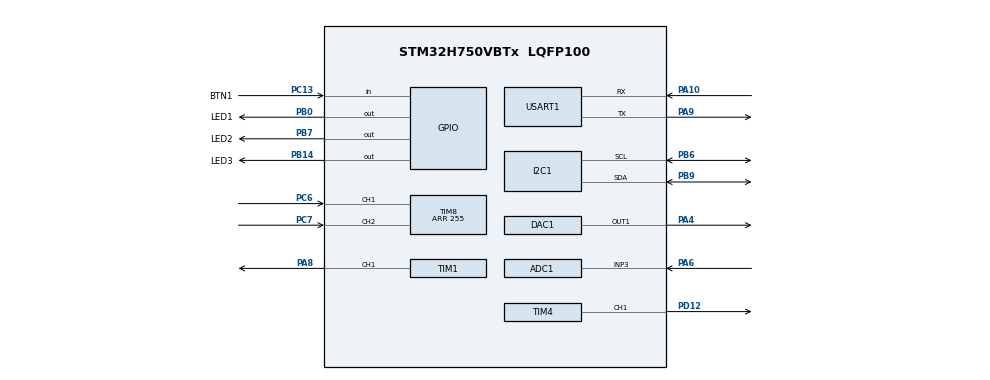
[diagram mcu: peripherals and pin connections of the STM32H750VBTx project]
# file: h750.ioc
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ADC1.Channel-0\#ChannelRegularConversion=ADC_CHANNEL_3
ADC1.ClockPrescaler=ADC_CLOCK_ASYNC_DIV8
ADC1.ContinuousConvMode=ENABLE
ADC1.ConversionDataManagement=ADC_CONVERSIONDATA_DMA_CIRCULAR
ADC1.DMAAccessModeView=ENABLE
ADC1.EOCSelection=ADC_EOC_SEQ_CONV
ADC1.Mode=ADC_DUALMODE_INTERL
ADC1.NbrOfConversionFlag=1
ADC1.OffsetNumber-0\#ChannelRegularConversion=ADC_OFFSET_NONE
ADC1.OffsetSignedSaturation-0\#ChannelRegularConversion=DISABLE
ADC1.Overrun=ADC_OVR_DATA_OVERWRITTEN
ADC1.Rank-0\#ChannelRegularConversion=1
ADC1.Resolution=ADC_RESOLUTION_8B
ADC1.SamplingTime-0\#ChannelRegularConversion=ADC_SAMPLETIME_32CYCLES_5
ADC1.TwoSamplingDelay=ADC_TWOSAMPLINGDELAY_2CYCLES
ADC1.master=1
ADC2.Channel-0\#ChannelRegularConversion=ADC_CHANNEL_3
ADC2.ClockPrescaler=ADC_CLOCK_ASYNC_DIV8
ADC2.ContinuousConvMode=ENABLE
ADC2.ConversionDataManagement=ADC_CONVERSIONDATA_DR
ADC2.DMAAccessModeView=ENABLE
ADC2.EOCSelection=ADC_EOC_SEQ_CONV
ADC2.Mode=ADC_DUALMODE_INTERL
ADC2.NbrOfConversionFlag=1
ADC2.OffsetNumber-0\#ChannelRegularConversion=ADC_OFFSET_NONE
ADC2.OffsetSignedSaturation-0\#ChannelRegularConversion=DISABLE
ADC2.Overrun=ADC_OVR_DATA_OVERWRITTEN
ADC2.Rank-0\#ChannelRegularConversion=1
ADC2.Resolution=ADC_RESOLUTION_8B
ADC2.SamplingTime-0\#ChannelRegularConversion=ADC_SAMPLETIME_32CYCLES_5
ADC2.TwoSamplingDelay=ADC_TWOSAMPLINGDELAY_2CYCLES
CORTEX_M7.CPU_DCache=Disabled
CORTEX_M7.CPU_ICache=Enabled
CORTEX_M7.MPU_Control=__NULL
DAC1.DAC1_OutputBuffer-DAC_OUT1=DAC_OUTPUTBUFFER_DISABLE
DAC1.DAC_Channel-DAC_OUT1=DAC_CHANNEL_1
DAC1.DAC_Trigger-DAC_OUT1=DAC_TRIGGER_T4_TRGO
DAC1.DAC_UserTrimming-DAC_OUT1=DAC_TRIMMING_FACTORY
DAC1.WaveGeneration-DAC_OUT1=DISABLE
Dma.ADC1.2.Direction=DMA_PERIPH_TO_MEMORY
Dma.ADC1.2.EventEnable=DISABLE
Dma.ADC1.2.FIFOMode=DMA_FIFOMODE_DISABLE
Dma.ADC1.2.Instance=DMA2_Stream0
Dma.ADC1.2.MemDataAlignment=DMA_MDATAALIGN_HALFWORD
Dma.ADC1.2.MemInc=DMA_MINC_ENABLE
Dma.ADC1.2.Mode=DMA_NORMAL
Dma.ADC1.2.PeriphDataAlignment=DMA_PDATAALIGN_HALFWORD
Dma.ADC1.2.PeriphInc=DMA_PINC_DISABLE
Dma.ADC1.2.Polarity=HAL_DMAMUX_REQ_GEN_RISING
Dma.ADC1.2.Priority=DMA_PRIORITY_VERY_HIGH
Dma.ADC1.2.RequestNumber=1
Dma.ADC1.2.SignalID=NONE
Dma.ADC1.2.SyncEnable=DISABLE
Dma.ADC1.2.SyncPolarity=HAL_DMAMUX_SYNC_NO_EVENT
Dma.ADC1.2.SyncRequestNumber=1
Dma.ADC1.2.SyncSignalID=NONE
Dma.DAC1_CH1.0.Direction=DMA_MEMORY_TO_PERIPH
Dma.DAC1_CH1.0.EventEnable=DISABLE
Dma.DAC1_CH1.0.FIFOMode=DMA_FIFOMODE_DISABLE
Dma.DAC1_CH1.0.Instance=DMA1_Stream2
Dma.DAC1_CH1.0.MemDataAlignment=DMA_MDATAALIGN_BYTE
Dma.DAC1_CH1.0.MemInc=DMA_MINC_ENABLE
Dma.DAC1_CH1.0.Mode=DMA_CIRCULAR
Dma.DAC1_CH1.0.PeriphDataAlignment=DMA_PDATAALIGN_BYTE
Dma.DAC1_CH1.0.PeriphInc=DMA_PINC_DISABLE
Dma.DAC1_CH1.0.Polarity=HAL_DMAMUX_REQ_GEN_RISING
Dma.DAC1_CH1.0.Priority=DMA_PRIORITY_HIGH
Dma.DAC1_CH1.0.RequestNumber=1
Dma.DAC1_CH1.0.SignalID=NONE
Dma.DAC1_CH1.0.SyncEnable=DISABLE
Dma.DAC1_CH1.0.SyncPolarity=HAL_DMAMUX_SYNC_NO_EVENT
Dma.DAC1_CH1.0.SyncRequestNumber=1
Dma.DAC1_CH1.0.SyncSignalID=NONE
Dma.Request0=DAC1_CH1
Dma.Request1=USART1_TX
Dma.Request2=ADC1
Dma.USART1_TX.1.Direction=DMA_MEMORY_TO_PERIPH
Dma.USART1_TX.1.EventEnable=DISABLE
Dma.USART1_TX.1.FIFOMode=DMA_FIFOMODE_DISABLE
Dma.USART1_TX.1.Instance=DMA1_Stream0
Dma.USART1_TX.1.MemDataAlignment=DMA_MDATAALIGN_BYTE
Dma.USART1_TX.1.MemInc=DMA_MINC_ENABLE
Dma.USART1_TX.1.Mode=DMA_NORMAL
Dma.USART1_TX.1.PeriphDataAlignment=DMA_PDATAALIGN_BYTE
Dma.USART1_TX.1.PeriphInc=DMA_PINC_DISABLE
Dma.USART1_TX.1.Polarity=HAL_DMAMUX_REQ_GEN_RISING
Dma.USART1_TX.1.Priority=DMA_PRIORITY_LOW
Dma.USART1_TX.1.RequestNumber=1
Dma.USART1_TX.1.SignalID=NONE
Dma.USART1_TX.1.SyncEnable=DISABLE
Dma.USART1_TX.1.SyncPolarity=HAL_DMAMUX_SYNC_NO_EVENT
Dma.USART1_TX.1.SyncRequestNumber=1
Dma.USART1_TX.1.SyncSignalID=NONE
I2C1.Timing=0x10C0ECFF
Mcu.Family=STM32H7
Mcu.Name=STM32H750VBTx
Mcu.Package=LQFP100
NVIC.DMA1_Stream0_IRQn=true\:0\:0\:false\:false\:true\:false\:true\:true
NVIC.DMA1_Stream2_IRQn=true\:0\:0\:false\:false\:true\:false\:true\:true
NVIC.DMA2_Stream0_IRQn=true\:0\:0\:false\:false\:true\:false\:true\:true
NVIC.PriorityGroup=NVIC_PRIORITYGROUP_4
PA10.Mode=Asynchronous
PA10.Signal=USART1_RX
PA13\ (JTMS/SWDIO).Mode=Serial_Wire
PA13\ (JTMS/SWDIO).Signal=DEBUG_JTMS-SWDIO
PA14\ (JTCK/SWCLK).Mode=Serial_Wire
PA14\ (JTCK/SWCLK).Signal=DEBUG_JTCK-SWCLK
PA4.Signal=COMP_DAC11_group
PA6.Signal=ADCx_INP3
PA8.GPIO_Speed=GPIO_SPEED_FREQ_HIGH
PA8.Signal=S_TIM1_CH1
PA9.Mode=Asynchronous
PA9.Signal=USART1_TX
PB0.GPIO_Label=LED1
PB0.GPIO_Speed=GPIO_SPEED_FREQ_LOW
PB0.Signal=GPIO_Output
PB14.GPIO_Label=LED3
PB14.GPIO_Speed=GPIO_SPEED_FREQ_LOW
PB14.Signal=GPIO_Output
PB6.Mode=I2C
PB6.Signal=I2C1_SCL
PB7.GPIO_Label=LED2
PB7.GPIO_Speed=GPIO_SPEED_FREQ_LOW
PB7.Signal=GPIO_Output
PB9.Mode=I2C
PB9.Signal=I2C1_SDA
PC13.GPIO_Label=BTN1
PC13.GPIO_PuPd=GPIO_PULLDOWN
PC13.Signal=GPIO_Input
PC6.GPIO_PuPd=GPIO_PULLUP
PC6.Signal=S_TIM8_CH1
PC7.GPIO_PuPd=GPIO_PULLUP
PC7.Signal=S_TIM8_CH2
PD0.Signal=FMC_D2_DA2
PD1.Signal=FMC_D3_DA3
PD10.Signal=FMC_D15_DA15
PD12.GPIO_Speed=GPIO_SPEED_FREQ_HIGH
PD12.Signal=S_TIM4_CH1
PD13.Signal=FMC_A18
PD14.Signal=FMC_D0_DA0
PD15.Signal=FMC_D1_DA1
PD4.Signal=FMC_NOE
PD5.Signal=FMC_NWE
PD7.Signal=FMC_NE1
PD8.Signal=FMC_D13_DA13
PD9.Signal=FMC_D14_DA14
PE10.Signal=FMC_D7_DA7
PE11.Signal=FMC_D8_DA8
PE12.Signal=FMC_D9_DA9
PE13.Signal=FMC_D10_DA10
PE14.Signal=FMC_D11_DA11
PE15.Signal=FMC_D12_DA12
PE7.Signal=FMC_D4_DA4
PE8.Signal=FMC_D5_DA5
PE9.Signal=FMC_D6_DA6
PH0-OSC_IN\ (PH0).Mode=HSE-External-Oscillator
PH0-OSC_IN\ (PH0).Signal=RCC_OSC_IN
PH1-OSC_OUT\ (PH1).Mode=HSE-External-Oscillator
PH1-OSC_OUT\ (PH1).Signal=RCC_OSC_OUT
ProjectManager.HeapSize=0x200
ProjectManager.StackSize=0x400
ProjectManager.TargetToolchain=STM32CubeIDE
RCC.ADCCLockSelection=RCC_ADCCLKSOURCE_PLL3
RCC.ADCFreq_Value=40000000
RCC.APB1Freq_Value=100000000
RCC.APB2Freq_Value=100000000
RCC.APB3Freq_Value=100000000
RCC.APB4Freq_Value=100000000
RCC.CortexFreq_Value=400000000
RCC.D1PPRE=RCC_APB3_DIV2
RCC.D2PPRE1=RCC_APB1_DIV2
RCC.D2PPRE2=RCC_APB2_DIV2
RCC.D3PPRE=RCC_APB4_DIV2
RCC.DIVM1=1
RCC.DIVM2=2
RCC.DIVM3=4
RCC.DIVN1=50
RCC.DIVN2=20
RCC.DIVN3=40
RCC.DIVR2=1
RCC.DIVR3=4
RCC.EnbaleCSS=true
RCC.FMCCLockSelection=RCC_FMCCLKSOURCE_PLL2
RCC.HCLKFreq_Value=200000000
RCC.HPRE=RCC_HCLK_DIV2
RCC.HSE_VALUE=16000000
RCC.LPTIM1CLockSelection=RCC_LPTIM1CLKSOURCE_PLL2
RCC.PLLSourceVirtual=RCC_PLLSOURCE_HSE
RCC.ProductRev=revY
RCC.SYSCLKFreq_VALUE=400000000
RCC.SYSCLKSource=RCC_SYSCLKSOURCE_PLLCLK
RCC.USBFreq_Value=400000000
SH.ADCx_INP3.0=ADC1_INP3,IN3-Single-Ended
SH.ADCx_INP3.1=ADC2_INP3,IN3-Single-Ended
SH.COMP_DAC11_group.0=DAC1_OUT1,DAC_OUT1
SH.FMC_A18.0=FMC_A18
SH.FMC_D0_DA0.0=FMC_D0
SH.FMC_D10_DA10.0=FMC_D10
SH.FMC_D11_DA11.0=FMC_D11
SH.FMC_D12_DA12.0=FMC_D12
SH.FMC_D13_DA13.0=FMC_D13
SH.FMC_D14_DA14.0=FMC_D14
SH.FMC_D15_DA15.0=FMC_D15
SH.FMC_D1_DA1.0=FMC_D1
SH.FMC_D2_DA2.0=FMC_D2
SH.FMC_D3_DA3.0=FMC_D3
SH.FMC_D4_DA4.0=FMC_D4
SH.FMC_D5_DA5.0=FMC_D5
SH.FMC_D6_DA6.0=FMC_D6
SH.FMC_D7_DA7.0=FMC_D7
SH.FMC_D8_DA8.0=FMC_D8
SH.FMC_D9_DA9.0=FMC_D9
SH.FMC_NOE.0=FMC_NOE
SH.FMC_NWE.0=FMC_NWE
SH.S_TIM1_CH1.0=TIM1_CH1,PWM Generation1 CH1
SH.S_TIM4_CH1.0=TIM4_CH1,PWM Generation1 CH1
SH.S_TIM8_CH1.0=TIM8_CH1,Encoder_Interface
SH.S_TIM8_CH2.0=TIM8_CH2,Encoder_Interface
TIM1.Channel-PWM\ Generation1\ CH1=TIM_CHANNEL_1
TIM1.Period=99
TIM1.Prescaler=99
TIM1.Pulse-PWM\ Generation1\ CH1=40
TIM4.Channel-PWM\ Generation1\ CH1=TIM_CHANNEL_1
TIM4.Period=5
TIM4.Prescaler=10
TIM4.Pulse-PWM\ Generation1\ CH1=3
TIM4.TIM_MasterOutputTrigger=TIM_TRGO_UPDATE
TIM8.EncoderMode=TIM_ENCODERMODE_TI12
TIM8.IC1Filter=6
TIM8.IC2Filter=6
TIM8.Period=255
USART1.DMADisableonRxErrorParam=ADVFEATURE_DMA_DISABLEONRXERROR
USART1.OverrunDisableParam=ADVFEATURE_OVERRUN_DISABLE
USART1.VirtualMode-Asynchronous=VM_ASYNC
VP_MEMORYMAP_VS_MEMORYMAP.Mode=CurAppReg
VP_TIM1_VS_ClockSourceINT.Mode=Internal
VP_TIM4_VS_ClockSourceINT.Mode=Internal
board=custom

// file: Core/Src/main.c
/* USER CODE BEGIN Header */
/**
  ******************************************************************************
  * @file           : main.c
  * @brief          : Main program body
  ******************************************************************************
  * @attention
  *
  * Copyright (c) 2026 STMicroelectronics.
  * All rights reserved.
  *
  * This software is licensed under terms that can be found in the LICENSE file
  * in the root directory of this software component.
  * If no LICENSE file comes with this software, it is provided AS-IS.
  *
  ******************************************************************************
  */
/* USER CODE END Header */
#include "main.h"

/* USER CODE BEGIN Includes */
#include "_main.h"

/* USER CODE END Includes */

void SystemClock_Config(void);
void PeriphCommonClock_Config(void);
static void MX_GPIO_Init(void);
static void MX_DMA_Init(void);
static void MX_USART1_UART_Init(void);
static void MX_TIM1_Init(void);
static void MX_TIM8_Init(void);
static void MX_DAC1_Init(void);
static void MX_TIM4_Init(void);
static void MX_ADC1_Init(void);
static void MX_ADC2_Init(void);
static void MX_I2C1_Init(void);

int main(void)
{

  /* Enable the CPU Cache */

  /* Enable I-Cache---------------------------------------------------------*/
  SCB_EnableICache();

  /* MCU Configuration--------------------------------------------------------*/

  /* Reset of all peripherals, Initializes the Flash interface and the Systick. */
  LL_APB4_GRP1_EnableClock(LL_APB4_GRP1_PERIPH_SYSCFG);

  /* System interrupt init*/
  NVIC_SetPriorityGrouping(NVIC_PRIORITYGROUP_4);

  /* SysTick_IRQn interrupt configuration */
  NVIC_SetPriority(SysTick_IRQn, NVIC_EncodePriority(NVIC_GetPriorityGrouping(),15, 0));

  /* Configure the system clock */
  SystemClock_Config();

  /* Configure the peripherals common clocks */
  PeriphCommonClock_Config();

  /* Initialize all configured peripherals */
  MX_GPIO_Init();
  MX_DMA_Init();
  MX_USART1_UART_Init();
  MX_TIM1_Init();
  MX_TIM8_Init();
  MX_DAC1_Init();
  MX_TIM4_Init();
  MX_ADC1_Init();
  MX_ADC2_Init();
  MX_I2C1_Init();
  /* USER CODE BEGIN 2 */

  // start uart
  DMA1_0_busy = 0;
  LL_DMA_EnableIT_TC(DMA1, LL_DMA_STREAM_0);
  LL_DMA_EnableIT_TE(DMA1, LL_DMA_STREAM_0);
  LL_USART_EnableDMAReq_TX(USART1);
  LL_USART_EnableDirectionTx(USART1);

  mainInitialize();

  /* USER CODE END 2 */

  /* Infinite loop */
  /* USER CODE BEGIN WHILE */

  // ReSharper disable once CppDFAEndlessLoop
  while (1)
  {
      mainCycle();
    /* USER CODE END WHILE */

  }
}

void SystemClock_Config(void)
{
  LL_FLASH_SetLatency(LL_FLASH_LATENCY_2);
  while(LL_FLASH_GetLatency()!= LL_FLASH_LATENCY_2)
  {
  }
  LL_PWR_ConfigSupply(LL_PWR_LDO_SUPPLY);
  LL_PWR_SetRegulVoltageScaling(LL_PWR_REGU_VOLTAGE_SCALE1);
  while (LL_PWR_IsActiveFlag_VOS() == 0)
  {
  }
  LL_RCC_HSE_Enable();

   /* Wait till HSE is ready */
  while(LL_RCC_HSE_IsReady() != 1)
  {

  }
  LL_RCC_HSE_EnableCSS();
  LL_RCC_PLL_SetSource(LL_RCC_PLLSOURCE_HSE);
  LL_RCC_PLL1P_Enable();
  LL_RCC_PLL1R_Enable();
  LL_RCC_PLL1_SetVCOInputRange(LL_RCC_PLLINPUTRANGE_8_16);
  LL_RCC_PLL1_SetVCOOutputRange(LL_RCC_PLLVCORANGE_WIDE);
  LL_RCC_PLL1_SetM(1);
  LL_RCC_PLL1_SetN(50);
  LL_RCC_PLL1_SetP(2);
  LL_RCC_PLL1_SetQ(2);
  LL_RCC_PLL1_SetR(2);
  LL_RCC_PLL1_Enable();

   /* Wait till PLL is ready */
  while(LL_RCC_PLL1_IsReady() != 1)
  {
  }

   /* Intermediate AHB prescaler 2 when target frequency clock is higher than 80 MHz */
   LL_RCC_SetAHBPrescaler(LL_RCC_AHB_DIV_2);

  LL_RCC_SetSysClkSource(LL_RCC_SYS_CLKSOURCE_PLL1);

   /* Wait till System clock is ready */
  while(LL_RCC_GetSysClkSource() != LL_RCC_SYS_CLKSOURCE_STATUS_PLL1)
  {

  }
  LL_RCC_SetSysPrescaler(LL_RCC_SYSCLK_DIV_1);
  LL_RCC_SetAHBPrescaler(LL_RCC_AHB_DIV_2);
  LL_RCC_SetAPB1Prescaler(LL_RCC_APB1_DIV_2);
  LL_RCC_SetAPB2Prescaler(LL_RCC_APB2_DIV_2);
  LL_RCC_SetAPB3Prescaler(LL_RCC_APB3_DIV_2);
  LL_RCC_SetAPB4Prescaler(LL_RCC_APB4_DIV_2);

  LL_Init1msTick(400000000);

  LL_SetSystemCoreClock(400000000);
  LL_RCC_HSE_EnableCSS();
}

void PeriphCommonClock_Config(void)
{
  LL_RCC_PLL3R_Enable();
  LL_RCC_PLL3_SetVCOInputRange(LL_RCC_PLLINPUTRANGE_4_8);
  LL_RCC_PLL3_SetVCOOutputRange(LL_RCC_PLLVCORANGE_MEDIUM);
  LL_RCC_PLL3_SetM(4);
  LL_RCC_PLL3_SetN(40);
  LL_RCC_PLL3_SetP(2);
  LL_RCC_PLL3_SetQ(2);
  LL_RCC_PLL3_SetR(4);
  LL_RCC_PLL3_Enable();

   /* Wait till PLL is ready */
  while(LL_RCC_PLL3_IsReady() != 1)
  {
  }

}

static void MX_ADC1_Init(void)
{

  LL_ADC_InitTypeDef ADC_InitStruct = {0};
  LL_ADC_REG_InitTypeDef ADC_REG_InitStruct = {0};
  LL_ADC_CommonInitTypeDef ADC_CommonInitStruct = {0};

  LL_GPIO_InitTypeDef GPIO_InitStruct = {0};

  LL_RCC_SetADCClockSource(LL_RCC_ADC_CLKSOURCE_PLL3R);

  /* Peripheral clock enable */
  LL_AHB1_GRP1_EnableClock(LL_AHB1_GRP1_PERIPH_ADC12);

  LL_AHB4_GRP1_EnableClock(LL_AHB4_GRP1_PERIPH_GPIOA);
  /**ADC1 GPIO Configuration
  PA6   ------> ADC1_INP3
  */
  GPIO_InitStruct.Pin = LL_GPIO_PIN_6;
  GPIO_InitStruct.Mode = LL_GPIO_MODE_ANALOG;
  GPIO_InitStruct.Pull = LL_GPIO_PULL_NO;
  LL_GPIO_Init(GPIOA, &GPIO_InitStruct);

  /* ADC1 DMA Init */

  /* ADC1 Init */
  LL_DMA_SetPeriphRequest(DMA2, LL_DMA_STREAM_0, LL_DMAMUX1_REQ_ADC1);

  LL_DMA_SetDataTransferDirection(DMA2, LL_DMA_STREAM_0, LL_DMA_DIRECTION_PERIPH_TO_MEMORY);

  LL_DMA_SetStreamPriorityLevel(DMA2, LL_DMA_STREAM_0, LL_DMA_PRIORITY_VERYHIGH);

  LL_DMA_SetMode(DMA2, LL_DMA_STREAM_0, LL_DMA_MODE_NORMAL);

  LL_DMA_SetPeriphIncMode(DMA2, LL_DMA_STREAM_0, LL_DMA_PERIPH_NOINCREMENT);

  LL_DMA_SetMemoryIncMode(DMA2, LL_DMA_STREAM_0, LL_DMA_MEMORY_INCREMENT);

  LL_DMA_SetPeriphSize(DMA2, LL_DMA_STREAM_0, LL_DMA_PDATAALIGN_HALFWORD);

  LL_DMA_SetMemorySize(DMA2, LL_DMA_STREAM_0, LL_DMA_MDATAALIGN_HALFWORD);

  LL_DMA_DisableFifoMode(DMA2, LL_DMA_STREAM_0);

  /** Common config
  */
  LL_ADC_SetOverSamplingScope(ADC1, LL_ADC_OVS_DISABLE);
  ADC_InitStruct.Resolution = LL_ADC_RESOLUTION_8B;
  ADC_InitStruct.LowPowerMode = LL_ADC_LP_MODE_NONE;
  ADC_InitStruct.LeftBitShift = LL_ADC_LEFT_BIT_SHIFT_NONE;
  LL_ADC_Init(ADC1, &ADC_InitStruct);
  ADC_REG_InitStruct.TriggerSource = LL_ADC_REG_TRIG_SOFTWARE;
  ADC_REG_InitStruct.SequencerLength = LL_ADC_REG_SEQ_SCAN_DISABLE;
  ADC_REG_InitStruct.SequencerDiscont = DISABLE;
  ADC_REG_InitStruct.ContinuousMode = LL_ADC_REG_CONV_CONTINUOUS;
  ADC_REG_InitStruct.Overrun = LL_ADC_REG_OVR_DATA_OVERWRITTEN;
  LL_ADC_REG_Init(ADC1, &ADC_REG_InitStruct);
  LL_ADC_REG_SetDataTransferMode(ADC1, LL_ADC_REG_DMA_TRANSFER_UNLIMITED);
  ADC_CommonInitStruct.CommonClock = LL_ADC_CLOCK_ASYNC_DIV8;
  ADC_CommonInitStruct.Multimode = LL_ADC_MULTI_DUAL_REG_INTERL;
  ADC_CommonInitStruct.MultiTwoSamplingDelay = LL_ADC_MULTI_TWOSMP_DELAY_2CYCLES_5;
  LL_ADC_CommonInit(__LL_ADC_COMMON_INSTANCE(ADC1), &ADC_CommonInitStruct);

  /* Disable ADC deep power down (enabled by default after reset state) */
  LL_ADC_DisableDeepPowerDown(ADC1);
  /* Enable ADC internal voltage regulator */
  LL_ADC_EnableInternalRegulator(ADC1);
  /* Delay for ADC internal voltage regulator stabilization. */
  /* Compute number of CPU cycles to wait for, from delay in us. */
  /* Note: Variable divided by 2 to compensate partially */
  /* CPU processing cycles (depends on compilation optimization). */
  /* Note: If system core clock frequency is below 200kHz, wait time */
  /* is only a few CPU processing cycles. */
  __IO uint32_t wait_loop_index;
  wait_loop_index = ((LL_ADC_DELAY_INTERNAL_REGUL_STAB_US * (SystemCoreClock / (100000 * 2))) / 10);
  while(wait_loop_index != 0)
  {
    wait_loop_index--;
  }

  /** Configure Regular Channel
  */
  LL_ADC_REG_SetSequencerRanks(ADC1, LL_ADC_REG_RANK_1, LL_ADC_CHANNEL_3);
  LL_ADC_SetChannelSamplingTime(ADC1, LL_ADC_CHANNEL_3, LL_ADC_SAMPLINGTIME_32CYCLES_5);
  LL_ADC_SetChannelSingleDiff(ADC1, LL_ADC_CHANNEL_3, LL_ADC_SINGLE_ENDED);
  LL_ADC_SetChannelPreselection(ADC1, LL_ADC_CHANNEL_3);
  /* USER CODE BEGIN ADC1_Init 2 */
  LL_ADC_SetMultiDMATransfer(ADC12_COMMON, LL_ADC_MULTI_REG_DMA_RES_8B);
  /* USER CODE END ADC1_Init 2 */

}

static void MX_ADC2_Init(void)
{

  LL_ADC_InitTypeDef ADC_InitStruct = {0};
  LL_ADC_REG_InitTypeDef ADC_REG_InitStruct = {0};

  LL_GPIO_InitTypeDef GPIO_InitStruct = {0};

  LL_RCC_SetADCClockSource(LL_RCC_ADC_CLKSOURCE_PLL3R);

  /* Peripheral clock enable */
  LL_AHB1_GRP1_EnableClock(LL_AHB1_GRP1_PERIPH_ADC12);

  LL_AHB4_GRP1_EnableClock(LL_AHB4_GRP1_PERIPH_GPIOA);
  /**ADC2 GPIO Configuration
  PA6   ------> ADC2_INP3
  */
  GPIO_InitStruct.Pin = LL_GPIO_PIN_6;
  GPIO_InitStruct.Mode = LL_GPIO_MODE_ANALOG;
  GPIO_InitStruct.Pull = LL_GPIO_PULL_NO;
  LL_GPIO_Init(GPIOA, &GPIO_InitStruct);

  /** Common config
  */
  LL_ADC_SetOverSamplingScope(ADC2, LL_ADC_OVS_DISABLE);
  ADC_InitStruct.Resolution = LL_ADC_RESOLUTION_8B;
  ADC_InitStruct.LowPowerMode = LL_ADC_LP_MODE_NONE;
  ADC_InitStruct.LeftBitShift = LL_ADC_LEFT_BIT_SHIFT_NONE;
  LL_ADC_Init(ADC2, &ADC_InitStruct);
  ADC_REG_InitStruct.SequencerLength = LL_ADC_REG_SEQ_SCAN_DISABLE;
  ADC_REG_InitStruct.SequencerDiscont = DISABLE;
  ADC_REG_InitStruct.ContinuousMode = LL_ADC_REG_CONV_CONTINUOUS;
  ADC_REG_InitStruct.Overrun = LL_ADC_REG_OVR_DATA_OVERWRITTEN;
  LL_ADC_REG_Init(ADC2, &ADC_REG_InitStruct);
  LL_ADC_REG_SetDataTransferMode(ADC2, LL_ADC_REG_DR_TRANSFER);

  /* Disable ADC deep power down (enabled by default after reset state) */
  LL_ADC_DisableDeepPowerDown(ADC2);
  /* Enable ADC internal voltage regulator */
  LL_ADC_EnableInternalRegulator(ADC2);
  /* Delay for ADC internal voltage regulator stabilization. */
  /* Compute number of CPU cycles to wait for, from delay in us. */
  /* Note: Variable divided by 2 to compensate partially */
  /* CPU processing cycles (depends on compilation optimization). */
  /* Note: If system core clock frequency is below 200kHz, wait time */
  /* is only a few CPU processing cycles. */
  __IO uint32_t wait_loop_index;
  wait_loop_index = ((LL_ADC_DELAY_INTERNAL_REGUL_STAB_US * (SystemCoreClock / (100000 * 2))) / 10);
  while(wait_loop_index != 0)
  {
    wait_loop_index--;
  }

  /** Configure Regular Channel
  */
  LL_ADC_REG_SetSequencerRanks(ADC2, LL_ADC_REG_RANK_1, LL_ADC_CHANNEL_3);
  LL_ADC_SetChannelSamplingTime(ADC2, LL_ADC_CHANNEL_3, LL_ADC_SAMPLINGTIME_32CYCLES_5);
  LL_ADC_SetChannelSingleDiff(ADC2, LL_ADC_CHANNEL_3, LL_ADC_SINGLE_ENDED);
  LL_ADC_SetChannelPreselection(ADC2, LL_ADC_CHANNEL_3);

}

static void MX_DAC1_Init(void)
{

  LL_DAC_InitTypeDef DAC_InitStruct = {0};

  LL_GPIO_InitTypeDef GPIO_InitStruct = {0};

  /* Peripheral clock enable */
  LL_APB1_GRP1_EnableClock(LL_APB1_GRP1_PERIPH_DAC12);

  LL_AHB4_GRP1_EnableClock(LL_AHB4_GRP1_PERIPH_GPIOA);
  /**DAC1 GPIO Configuration
  PA4   ------> DAC1_OUT1
  */
  GPIO_InitStruct.Pin = LL_GPIO_PIN_4;
  GPIO_InitStruct.Mode = LL_GPIO_MODE_ANALOG;
  GPIO_InitStruct.Pull = LL_GPIO_PULL_NO;
  LL_GPIO_Init(GPIOA, &GPIO_InitStruct);

  /* DAC1 DMA Init */

  /* DAC1_CH1 Init */
  LL_DMA_SetPeriphRequest(DMA1, LL_DMA_STREAM_2, LL_DMAMUX1_REQ_DAC1_CH1);

  LL_DMA_SetDataTransferDirection(DMA1, LL_DMA_STREAM_2, LL_DMA_DIRECTION_MEMORY_TO_PERIPH);

  LL_DMA_SetStreamPriorityLevel(DMA1, LL_DMA_STREAM_2, LL_DMA_PRIORITY_HIGH);

  LL_DMA_SetMode(DMA1, LL_DMA_STREAM_2, LL_DMA_MODE_CIRCULAR);

  LL_DMA_SetPeriphIncMode(DMA1, LL_DMA_STREAM_2, LL_DMA_PERIPH_NOINCREMENT);

  LL_DMA_SetMemoryIncMode(DMA1, LL_DMA_STREAM_2, LL_DMA_MEMORY_INCREMENT);

  LL_DMA_SetPeriphSize(DMA1, LL_DMA_STREAM_2, LL_DMA_PDATAALIGN_BYTE);

  LL_DMA_SetMemorySize(DMA1, LL_DMA_STREAM_2, LL_DMA_MDATAALIGN_BYTE);

  LL_DMA_DisableFifoMode(DMA1, LL_DMA_STREAM_2);

  /** DAC channel OUT1 config
  */
  DAC_InitStruct.TriggerSource = LL_DAC_TRIG_EXT_TIM4_TRGO;
  DAC_InitStruct.WaveAutoGeneration = LL_DAC_WAVE_AUTO_GENERATION_NONE;
  DAC_InitStruct.OutputBuffer = LL_DAC_OUTPUT_BUFFER_DISABLE;
  DAC_InitStruct.OutputConnection = LL_DAC_OUTPUT_CONNECT_GPIO;
  DAC_InitStruct.OutputMode = LL_DAC_OUTPUT_MODE_NORMAL;
  LL_DAC_Init(DAC1, LL_DAC_CHANNEL_1, &DAC_InitStruct);
  LL_DAC_EnableTrigger(DAC1, LL_DAC_CHANNEL_1);

}

static void MX_I2C1_Init(void)
{

  LL_I2C_InitTypeDef I2C_InitStruct = {0};

  LL_GPIO_InitTypeDef GPIO_InitStruct = {0};

  LL_RCC_SetI2CClockSource(LL_RCC_I2C123_CLKSOURCE_PCLK1);

  LL_AHB4_GRP1_EnableClock(LL_AHB4_GRP1_PERIPH_GPIOB);
  /**I2C1 GPIO Configuration
  PB6   ------> I2C1_SCL
  PB9   ------> I2C1_SDA
  */
  GPIO_InitStruct.Pin = LL_GPIO_PIN_6|LL_GPIO_PIN_9;
  GPIO_InitStruct.Mode = LL_GPIO_MODE_ALTERNATE;
  GPIO_InitStruct.Speed = LL_GPIO_SPEED_FREQ_LOW;
  GPIO_InitStruct.OutputType = LL_GPIO_OUTPUT_OPENDRAIN;
  GPIO_InitStruct.Pull = LL_GPIO_PULL_NO;
  GPIO_InitStruct.Alternate = LL_GPIO_AF_4;
  LL_GPIO_Init(GPIOB, &GPIO_InitStruct);

  /* Peripheral clock enable */
  LL_APB1_GRP1_EnableClock(LL_APB1_GRP1_PERIPH_I2C1);

  /** I2C Initialization
  */
  LL_I2C_EnableAutoEndMode(I2C1);
  LL_I2C_SetOwnAddress2(I2C1, 0, LL_I2C_OWNADDRESS2_NOMASK);
  LL_I2C_DisableOwnAddress2(I2C1);
  LL_I2C_DisableGeneralCall(I2C1);
  LL_I2C_EnableClockStretching(I2C1);
  I2C_InitStruct.PeripheralMode = LL_I2C_MODE_I2C;
  I2C_InitStruct.Timing = 0x10C0ECFF;
  I2C_InitStruct.AnalogFilter = LL_I2C_ANALOGFILTER_ENABLE;
  I2C_InitStruct.DigitalFilter = 0;
  I2C_InitStruct.OwnAddress1 = 0;
  I2C_InitStruct.TypeAcknowledge = LL_I2C_ACK;
  I2C_InitStruct.OwnAddrSize = LL_I2C_OWNADDRESS1_7BIT;
  LL_I2C_Init(I2C1, &I2C_InitStruct);

}

static void MX_TIM1_Init(void)
{

  LL_TIM_InitTypeDef TIM_InitStruct = {0};
  LL_TIM_OC_InitTypeDef TIM_OC_InitStruct = {0};
  LL_TIM_BDTR_InitTypeDef TIM_BDTRInitStruct = {0};

  LL_GPIO_InitTypeDef GPIO_InitStruct = {0};

  /* Peripheral clock enable */
  LL_APB2_GRP1_EnableClock(LL_APB2_GRP1_PERIPH_TIM1);

  TIM_InitStruct.Prescaler = 99;
  TIM_InitStruct.CounterMode = LL_TIM_COUNTERMODE_UP;
  TIM_InitStruct.Autoreload = 99;
  TIM_InitStruct.ClockDivision = LL_TIM_CLOCKDIVISION_DIV1;
  TIM_InitStruct.RepetitionCounter = 0;
  LL_TIM_Init(TIM1, &TIM_InitStruct);
  LL_TIM_DisableARRPreload(TIM1);
  LL_TIM_SetClockSource(TIM1, LL_TIM_CLOCKSOURCE_INTERNAL);
  LL_TIM_OC_EnablePreload(TIM1, LL_TIM_CHANNEL_CH1);
  TIM_OC_InitStruct.OCMode = LL_TIM_OCMODE_PWM1;
  TIM_OC_InitStruct.OCState = LL_TIM_OCSTATE_DISABLE;
  TIM_OC_InitStruct.OCNState = LL_TIM_OCSTATE_DISABLE;
  TIM_OC_InitStruct.CompareValue = 40;
  TIM_OC_InitStruct.OCPolarity = LL_TIM_OCPOLARITY_HIGH;
  TIM_OC_InitStruct.OCNPolarity = LL_TIM_OCPOLARITY_HIGH;
  TIM_OC_InitStruct.OCIdleState = LL_TIM_OCIDLESTATE_LOW;
  TIM_OC_InitStruct.OCNIdleState = LL_TIM_OCIDLESTATE_LOW;
  LL_TIM_OC_Init(TIM1, LL_TIM_CHANNEL_CH1, &TIM_OC_InitStruct);
  LL_TIM_OC_DisableFast(TIM1, LL_TIM_CHANNEL_CH1);
  LL_TIM_SetTriggerOutput(TIM1, LL_TIM_TRGO_RESET);
  LL_TIM_SetTriggerOutput2(TIM1, LL_TIM_TRGO2_RESET);
  LL_TIM_DisableMasterSlaveMode(TIM1);
  TIM_BDTRInitStruct.OSSRState = LL_TIM_OSSR_DISABLE;
  TIM_BDTRInitStruct.OSSIState = LL_TIM_OSSI_DISABLE;
  TIM_BDTRInitStruct.LockLevel = LL_TIM_LOCKLEVEL_OFF;
  TIM_BDTRInitStruct.DeadTime = 0;
  TIM_BDTRInitStruct.BreakState = LL_TIM_BREAK_DISABLE;
  TIM_BDTRInitStruct.BreakPolarity = LL_TIM_BREAK_POLARITY_HIGH;
  TIM_BDTRInitStruct.BreakFilter = LL_TIM_BREAK_FILTER_FDIV1;
  TIM_BDTRInitStruct.Break2State = LL_TIM_BREAK2_DISABLE;
  TIM_BDTRInitStruct.Break2Polarity = LL_TIM_BREAK2_POLARITY_HIGH;
  TIM_BDTRInitStruct.Break2Filter = LL_TIM_BREAK2_FILTER_FDIV1;
  TIM_BDTRInitStruct.AutomaticOutput = LL_TIM_AUTOMATICOUTPUT_DISABLE;
  LL_TIM_BDTR_Init(TIM1, &TIM_BDTRInitStruct);
  LL_AHB4_GRP1_EnableClock(LL_AHB4_GRP1_PERIPH_GPIOA);
  /**TIM1 GPIO Configuration
  PA8   ------> TIM1_CH1
  */
  GPIO_InitStruct.Pin = LL_GPIO_PIN_8;
  GPIO_InitStruct.Mode = LL_GPIO_MODE_ALTERNATE;
  GPIO_InitStruct.Speed = LL_GPIO_SPEED_FREQ_HIGH;
  GPIO_InitStruct.OutputType = LL_GPIO_OUTPUT_PUSHPULL;
  GPIO_InitStruct.Pull = LL_GPIO_PULL_NO;
  GPIO_InitStruct.Alternate = LL_GPIO_AF_1;
  LL_GPIO_Init(GPIOA, &GPIO_InitStruct);

}

static void MX_TIM4_Init(void)
{

  LL_TIM_InitTypeDef TIM_InitStruct = {0};
  LL_TIM_OC_InitTypeDef TIM_OC_InitStruct = {0};

  LL_GPIO_InitTypeDef GPIO_InitStruct = {0};

  /* Peripheral clock enable */
  LL_APB1_GRP1_EnableClock(LL_APB1_GRP1_PERIPH_TIM4);

  TIM_InitStruct.Prescaler = 10;
  TIM_InitStruct.CounterMode = LL_TIM_COUNTERMODE_UP;
  TIM_InitStruct.Autoreload = 5;
  TIM_InitStruct.ClockDivision = LL_TIM_CLOCKDIVISION_DIV1;
  LL_TIM_Init(TIM4, &TIM_InitStruct);
  LL_TIM_DisableARRPreload(TIM4);
  LL_TIM_SetClockSource(TIM4, LL_TIM_CLOCKSOURCE_INTERNAL);
  LL_TIM_OC_EnablePreload(TIM4, LL_TIM_CHANNEL_CH1);
  TIM_OC_InitStruct.OCMode = LL_TIM_OCMODE_PWM1;
  TIM_OC_InitStruct.OCState = LL_TIM_OCSTATE_DISABLE;
  TIM_OC_InitStruct.OCNState = LL_TIM_OCSTATE_DISABLE;
  TIM_OC_InitStruct.CompareValue = 3;
  TIM_OC_InitStruct.OCPolarity = LL_TIM_OCPOLARITY_HIGH;
  LL_TIM_OC_Init(TIM4, LL_TIM_CHANNEL_CH1, &TIM_OC_InitStruct);
  LL_TIM_OC_DisableFast(TIM4, LL_TIM_CHANNEL_CH1);
  LL_TIM_SetTriggerOutput(TIM4, LL_TIM_TRGO_UPDATE);
  LL_TIM_DisableMasterSlaveMode(TIM4);
  LL_AHB4_GRP1_EnableClock(LL_AHB4_GRP1_PERIPH_GPIOD);
  /**TIM4 GPIO Configuration
  PD12   ------> TIM4_CH1
  */
  GPIO_InitStruct.Pin = LL_GPIO_PIN_12;
  GPIO_InitStruct.Mode = LL_GPIO_MODE_ALTERNATE;
  GPIO_InitStruct.Speed = LL_GPIO_SPEED_FREQ_HIGH;
  GPIO_InitStruct.OutputType = LL_GPIO_OUTPUT_PUSHPULL;
  GPIO_InitStruct.Pull = LL_GPIO_PULL_NO;
  GPIO_InitStruct.Alternate = LL_GPIO_AF_2;
  LL_GPIO_Init(GPIOD, &GPIO_InitStruct);

}

static void MX_TIM8_Init(void)
{

  LL_TIM_InitTypeDef TIM_InitStruct = {0};

  LL_GPIO_InitTypeDef GPIO_InitStruct = {0};

  /* Peripheral clock enable */
  LL_APB2_GRP1_EnableClock(LL_APB2_GRP1_PERIPH_TIM8);

  LL_AHB4_GRP1_EnableClock(LL_AHB4_GRP1_PERIPH_GPIOC);
  /**TIM8 GPIO Configuration
  PC6   ------> TIM8_CH1
  PC7   ------> TIM8_CH2
  */
  GPIO_InitStruct.Pin = LL_GPIO_PIN_6|LL_GPIO_PIN_7;
  GPIO_InitStruct.Mode = LL_GPIO_MODE_ALTERNATE;
  GPIO_InitStruct.Speed = LL_GPIO_SPEED_FREQ_LOW;
  GPIO_InitStruct.OutputType = LL_GPIO_OUTPUT_PUSHPULL;
  GPIO_InitStruct.Pull = LL_GPIO_PULL_UP;
  GPIO_InitStruct.Alternate = LL_GPIO_AF_3;
  LL_GPIO_Init(GPIOC, &GPIO_InitStruct);

  TIM_InitStruct.Prescaler = 0;
  TIM_InitStruct.CounterMode = LL_TIM_COUNTERMODE_UP;
  TIM_InitStruct.Autoreload = 255;
  TIM_InitStruct.ClockDivision = LL_TIM_CLOCKDIVISION_DIV1;
  TIM_InitStruct.RepetitionCounter = 0;
  LL_TIM_Init(TIM8, &TIM_InitStruct);
  LL_TIM_DisableARRPreload(TIM8);
  LL_TIM_SetEncoderMode(TIM8, LL_TIM_ENCODERMODE_X4_TI12);
  LL_TIM_IC_SetActiveInput(TIM8, LL_TIM_CHANNEL_CH1, LL_TIM_ACTIVEINPUT_DIRECTTI);
  LL_TIM_IC_SetPrescaler(TIM8, LL_TIM_CHANNEL_CH1, LL_TIM_ICPSC_DIV1);
  LL_TIM_IC_SetFilter(TIM8, LL_TIM_CHANNEL_CH1, LL_TIM_IC_FILTER_FDIV4_N6);
  LL_TIM_IC_SetPolarity(TIM8, LL_TIM_CHANNEL_CH1, LL_TIM_IC_POLARITY_RISING);
  LL_TIM_IC_SetActiveInput(TIM8, LL_TIM_CHANNEL_CH2, LL_TIM_ACTIVEINPUT_DIRECTTI);
  LL_TIM_IC_SetPrescaler(TIM8, LL_TIM_CHANNEL_CH2, LL_TIM_ICPSC_DIV1);
  LL_TIM_IC_SetFilter(TIM8, LL_TIM_CHANNEL_CH2, LL_TIM_IC_FILTER_FDIV4_N6);
  LL_TIM_IC_SetPolarity(TIM8, LL_TIM_CHANNEL_CH2, LL_TIM_IC_POLARITY_RISING);
  LL_TIM_SetTriggerOutput(TIM8, LL_TIM_TRGO_RESET);
  LL_TIM_SetTriggerOutput2(TIM8, LL_TIM_TRGO2_RESET);
  LL_TIM_DisableMasterSlaveMode(TIM8);

}

static void MX_USART1_UART_Init(void)
{

  LL_USART_InitTypeDef USART_InitStruct = {0};

  LL_GPIO_InitTypeDef GPIO_InitStruct = {0};

  LL_RCC_SetUSARTClockSource(LL_RCC_USART16_CLKSOURCE_PCLK2);

  /* Peripheral clock enable */
  LL_APB2_GRP1_EnableClock(LL_APB2_GRP1_PERIPH_USART1);

  LL_AHB4_GRP1_EnableClock(LL_AHB4_GRP1_PERIPH_GPIOA);
  /**USART1 GPIO Configuration
  PA9   ------> USART1_TX
  PA10   ------> USART1_RX
  */
  GPIO_InitStruct.Pin = LL_GPIO_PIN_9|LL_GPIO_PIN_10;
  GPIO_InitStruct.Mode = LL_GPIO_MODE_ALTERNATE;
  GPIO_InitStruct.Speed = LL_GPIO_SPEED_FREQ_LOW;
  GPIO_InitStruct.OutputType = LL_GPIO_OUTPUT_PUSHPULL;
  GPIO_InitStruct.Pull = LL_GPIO_PULL_NO;
  GPIO_InitStruct.Alternate = LL_GPIO_AF_7;
  LL_GPIO_Init(GPIOA, &GPIO_InitStruct);

  /* USART1 DMA Init */

  /* USART1_TX Init */
  LL_DMA_SetPeriphRequest(DMA1, LL_DMA_STREAM_0, LL_DMAMUX1_REQ_USART1_TX);

  LL_DMA_SetDataTransferDirection(DMA1, LL_DMA_STREAM_0, LL_DMA_DIRECTION_MEMORY_TO_PERIPH);

  LL_DMA_SetStreamPriorityLevel(DMA1, LL_DMA_STREAM_0, LL_DMA_PRIORITY_LOW);

  LL_DMA_SetMode(DMA1, LL_DMA_STREAM_0, LL_DMA_MODE_NORMAL);

  LL_DMA_SetPeriphIncMode(DMA1, LL_DMA_STREAM_0, LL_DMA_PERIPH_NOINCREMENT);

  LL_DMA_SetMemoryIncMode(DMA1, LL_DMA_STREAM_0, LL_DMA_MEMORY_INCREMENT);

  LL_DMA_SetPeriphSize(DMA1, LL_DMA_STREAM_0, LL_DMA_PDATAALIGN_BYTE);

  LL_DMA_SetMemorySize(DMA1, LL_DMA_STREAM_0, LL_DMA_MDATAALIGN_BYTE);

  LL_DMA_DisableFifoMode(DMA1, LL_DMA_STREAM_0);

  USART_InitStruct.PrescalerValue = LL_USART_PRESCALER_DIV1;
  USART_InitStruct.BaudRate = 115200;
  USART_InitStruct.DataWidth = LL_USART_DATAWIDTH_8B;
  USART_InitStruct.StopBits = LL_USART_STOPBITS_1;
  USART_InitStruct.Parity = LL_USART_PARITY_NONE;
  USART_InitStruct.TransferDirection = LL_USART_DIRECTION_TX_RX;
  USART_InitStruct.HardwareFlowControl = LL_USART_HWCONTROL_NONE;
  USART_InitStruct.OverSampling = LL_USART_OVERSAMPLING_16;
  LL_USART_Init(USART1, &USART_InitStruct);
  LL_USART_SetTXFIFOThreshold(USART1, LL_USART_FIFOTHRESHOLD_1_8);
  LL_USART_SetRXFIFOThreshold(USART1, LL_USART_FIFOTHRESHOLD_1_8);
  LL_USART_DisableFIFO(USART1);
  LL_USART_DisableOverrunDetect(USART1);
  LL_USART_DisableDMADeactOnRxErr(USART1);
  LL_USART_ConfigAsyncMode(USART1);

  LL_USART_Enable(USART1);

  /* Polling USART1 initialisation */
  while((!(LL_USART_IsActiveFlag_TEACK(USART1))) || (!(LL_USART_IsActiveFlag_REACK(USART1))))
  {
  }

}

static void MX_DMA_Init(void)
{

  /* Init with LL driver */
  /* DMA controller clock enable */
  LL_AHB1_GRP1_EnableClock(LL_AHB1_GRP1_PERIPH_DMA1);
  LL_AHB1_GRP1_EnableClock(LL_AHB1_GRP1_PERIPH_DMA2);

  /* DMA interrupt init */
  /* DMA1_Stream0_IRQn interrupt configuration */
  NVIC_SetPriority(DMA1_Stream0_IRQn, NVIC_EncodePriority(NVIC_GetPriorityGrouping(),0, 0));
  NVIC_EnableIRQ(DMA1_Stream0_IRQn);
  /* DMA1_Stream2_IRQn interrupt configuration */
  NVIC_SetPriority(DMA1_Stream2_IRQn, NVIC_EncodePriority(NVIC_GetPriorityGrouping(),0, 0));
  NVIC_EnableIRQ(DMA1_Stream2_IRQn);
  /* DMA2_Stream0_IRQn interrupt configuration */
  NVIC_SetPriority(DMA2_Stream0_IRQn, NVIC_EncodePriority(NVIC_GetPriorityGrouping(),0, 0));
  NVIC_EnableIRQ(DMA2_Stream0_IRQn);

}

static void MX_GPIO_Init(void)
{
  LL_GPIO_InitTypeDef GPIO_InitStruct = {0};

  /* GPIO Ports Clock Enable */
  LL_AHB4_GRP1_EnableClock(LL_AHB4_GRP1_PERIPH_GPIOC);
  LL_AHB4_GRP1_EnableClock(LL_AHB4_GRP1_PERIPH_GPIOH);
  LL_AHB4_GRP1_EnableClock(LL_AHB4_GRP1_PERIPH_GPIOA);
  LL_AHB4_GRP1_EnableClock(LL_AHB4_GRP1_PERIPH_GPIOB);
  LL_AHB4_GRP1_EnableClock(LL_AHB4_GRP1_PERIPH_GPIOE);
  LL_AHB4_GRP1_EnableClock(LL_AHB4_GRP1_PERIPH_GPIOD);

  /**/
  LL_GPIO_ResetOutputPin(GPIOB, LED1_Pin|LED3_Pin|LED2_Pin);

  /**/
  GPIO_InitStruct.Pin = BTN1_Pin;
  GPIO_InitStruct.Mode = LL_GPIO_MODE_INPUT;
  GPIO_InitStruct.Pull = LL_GPIO_PULL_DOWN;
  LL_GPIO_Init(BTN1_GPIO_Port, &GPIO_InitStruct);

  /**/
  GPIO_InitStruct.Pin = LED1_Pin|LED3_Pin|LED2_Pin;
  GPIO_InitStruct.Mode = LL_GPIO_MODE_OUTPUT;
  GPIO_InitStruct.Speed = LL_GPIO_SPEED_FREQ_LOW;
  GPIO_InitStruct.OutputType = LL_GPIO_OUTPUT_PUSHPULL;
  GPIO_InitStruct.Pull = LL_GPIO_PULL_NO;
  LL_GPIO_Init(GPIOB, &GPIO_InitStruct);

  /**/
  GPIO_InitStruct.Pin = LL_GPIO_PIN_7|LL_GPIO_PIN_8|LL_GPIO_PIN_9|LL_GPIO_PIN_10
                          |LL_GPIO_PIN_11|LL_GPIO_PIN_12|LL_GPIO_PIN_13|LL_GPIO_PIN_14
                          |LL_GPIO_PIN_15;
  GPIO_InitStruct.Mode = LL_GPIO_MODE_ALTERNATE;
  GPIO_InitStruct.Speed = LL_GPIO_SPEED_FREQ_VERY_HIGH;
  GPIO_InitStruct.OutputType = LL_GPIO_OUTPUT_PUSHPULL;
  GPIO_InitStruct.Pull = LL_GPIO_PULL_NO;
  GPIO_InitStruct.Alternate = LL_GPIO_AF_12;
  LL_GPIO_Init(GPIOE, &GPIO_InitStruct);

  /**/
  GPIO_InitStruct.Pin = LL_GPIO_PIN_8|LL_GPIO_PIN_9|LL_GPIO_PIN_10|LL_GPIO_PIN_13
                          |LL_GPIO_PIN_14|LL_GPIO_PIN_15|LL_GPIO_PIN_0|LL_GPIO_PIN_1
                          |LL_GPIO_PIN_4|LL_GPIO_PIN_5|LL_GPIO_PIN_7;
  GPIO_InitStruct.Mode = LL_GPIO_MODE_ALTERNATE;
  GPIO_InitStruct.Speed = LL_GPIO_SPEED_FREQ_VERY_HIGH;
  GPIO_InitStruct.OutputType = LL_GPIO_OUTPUT_PUSHPULL;
  GPIO_InitStruct.Pull = LL_GPIO_PULL_NO;
  GPIO_InitStruct.Alternate = LL_GPIO_AF_12;
  LL_GPIO_Init(GPIOD, &GPIO_InitStruct);

}

void Error_Handler(void)
{
  /* USER CODE BEGIN Error_Handler_Debug */
  /* User can add his own implementation to report the HAL error return state */
  __disable_irq();
  // ReSharper disable once CppDFAEndlessLoop
  while (1)
  {
  }
  /* USER CODE END Error_Handler_Debug */
}
